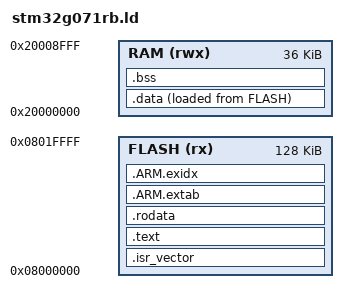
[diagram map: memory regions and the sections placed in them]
MEMORY {
    FLASH (rx)  : ORIGIN = 0x08000000, LENGTH = 128K
    RAM   (rwx) : ORIGIN = 0x20000000, LENGTH = 36K
}

_estack = ORIGIN(RAM) + LENGTH(RAM);

ENTRY(_start);

SECTIONS {
    .isr_vector : {
        . = ALIGN(4);
        KEEP(*(.isr_vector))
        . = ALIGN(4);
    } > FLASH

    .text : {
        . = ALIGN(4);
        *(.text)
        *(.text*)
        . = ALIGN(4);
    } > FLASH

    .rodata : {
        . = ALIGN(4);
        *(.rodata)
        *(.rodata*)
        . = ALIGN(4);
    } > FLASH

    _sidata = LOADADDR(.data);

    .data : {
        . = ALIGN(4);
        _sdata = .;
        *(.data)
        *(.data*)
        . = ALIGN(4);
        _edata = .;
    } > RAM AT> FLASH

    .bss : {
        . = ALIGN(4);
        _sbss = .;
        *(.bss)
        *(.bss*)
        *(COMMON)
        . = ALIGN(4);
        _ebss = .;
    } > RAM

    .ARM.extab : {
        *(.ARM.extab*)
    } > FLASH

    .ARM.exidx : {
        *(.ARM.exidx*)
    } > FLASH

    /DISCARD/ : {
        *(.ARM.attributes*)
        *(.comment)
        *(.eh_frame*)
    }
}
